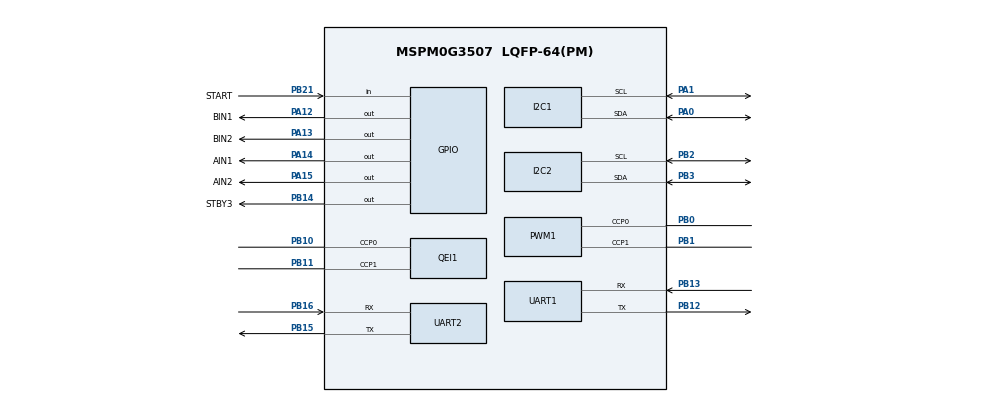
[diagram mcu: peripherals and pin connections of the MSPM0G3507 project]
/**
 * These arguments were used when this file was generated. They will be automatically applied on subsequent loads
 * via the GUI or CLI. Run CLI with '--help' for additional information on how to override these arguments.
 * @cliArgs --device "MSPM0G350X" --part "Default" --package "LQFP-64(PM)" --product "mspm0_sdk@2.02.00.05"
 * @v2CliArgs --device "MSPM0G3507" --package "LQFP-64(PM)" --product "mspm0_sdk@2.02.00.05"
 * @versions {"tool":"1.21.1+3772"}
 */

/**
 * Import the modules used in this configuration.
 */
const GPIO   = scripting.addModule("/ti/driverlib/GPIO", {}, false);
const GPIO1  = GPIO.addInstance();
const GPIO2  = GPIO.addInstance();
const GPIO3  = GPIO.addInstance();
const ADC12  = scripting.addModule("/ti/driverlib/ADC12", {}, false);
const ADC121 = ADC12.addInstance();
const I2C    = scripting.addModule("/ti/driverlib/I2C", {}, false);
const I2C1   = I2C.addInstance();
const I2C2   = I2C.addInstance();
const PWM    = scripting.addModule("/ti/driverlib/PWM", {}, false);
const PWM1   = PWM.addInstance();
const QEI    = scripting.addModule("/ti/driverlib/QEI", {}, false);
const QEI1   = QEI.addInstance();
const SYSCTL = scripting.addModule("/ti/driverlib/SYSCTL");
const UART   = scripting.addModule("/ti/driverlib/UART", {}, false);
const UART1  = UART.addInstance();
const UART2  = UART.addInstance();
const WWDT   = scripting.addModule("/ti/driverlib/WWDT", {}, false);
const WWDT1  = WWDT.addInstance();

/**
 * Write custom configuration values to the imported modules.
 */
GPIO1.$name                         = "STBY";
GPIO1.port                          = "PORTB";
GPIO1.associatedPins[0].$name       = "STBY3";
GPIO1.associatedPins[0].pin.$assign = "PB14";

const Board = scripting.addModule("/ti/driverlib/Board", {}, false);

GPIO2.$name                         = "MOTO";
GPIO2.port                          = "PORTA";
GPIO2.associatedPins.create(4);
GPIO2.associatedPins[0].$name       = "AIN1";
GPIO2.associatedPins[0].pin.$assign = "PA14";
GPIO2.associatedPins[1].$name       = "AIN2";
GPIO2.associatedPins[1].pin.$assign = "PA15";
GPIO2.associatedPins[2].$name       = "BIN1";
GPIO2.associatedPins[2].pin.$assign = "PA12";
GPIO2.associatedPins[3].$name       = "BIN2";
GPIO2.associatedPins[3].pin.$assign = "PA13";

GPIO3.$name                              = "KEY";
GPIO3.port                               = "PORTB";
GPIO3.associatedPins[0].$name            = "START";
GPIO3.associatedPins[0].direction        = "INPUT";
GPIO3.associatedPins[0].internalResistor = "PULL_UP";
GPIO3.associatedPins[0].pin.$assign      = "PB21";

ADC121.$name                      = "BAT_ADC";
ADC121.sampClkSrc                 = "DL_ADC12_CLOCK_ULPCLK";
ADC121.sampClkDiv                 = "DL_ADC12_CLOCK_DIVIDE_8";
ADC121.adcMem0chansel             = "DL_ADC12_INPUT_CHAN_0";
ADC121.sampleTime0                = "125 us";
ADC121.powerDownMode              = "DL_ADC12_POWER_DOWN_MODE_MANUAL";
ADC121.peripheral.$assign         = "ADC0";
ADC121.peripheral.adcPin0.$assign = "PA27";
ADC121.adcPin0Config.$name        = "ti_driverlib_gpio_GPIOPinGeneric12";

I2C1.$name                             = "OLED";
I2C1.basicEnableController             = true;
I2C1.basicControllerStandardBusSpeed   = "Standard";
I2C1.peripheral.$assign                = "I2C0";
I2C1.peripheral.sdaPin.$assign         = "PA0";
I2C1.peripheral.sclPin.$assign         = "PA1";
I2C1.sdaPinConfig.$name                = "ti_driverlib_gpio_GPIOPinGeneric0";
I2C1.sdaPinConfig.hideOutputInversion  = scripting.forceWrite(false);
I2C1.sdaPinConfig.onlyInternalResistor = scripting.forceWrite(false);
I2C1.sdaPinConfig.passedPeripheralType = scripting.forceWrite("Digital");
I2C1.sclPinConfig.$name                = "ti_driverlib_gpio_GPIOPinGeneric1";
I2C1.sclPinConfig.hideOutputInversion  = scripting.forceWrite(false);
I2C1.sclPinConfig.onlyInternalResistor = scripting.forceWrite(false);
I2C1.sclPinConfig.passedPeripheralType = scripting.forceWrite("Digital");

I2C2.$name                             = "IMU20948";
I2C2.basicEnableController             = true;
I2C2.basicControllerStandardBusSpeed   = "Standard";
I2C2.peripheral.$assign                = "I2C1";
I2C2.peripheral.sdaPin.$assign         = "PB3";
I2C2.peripheral.sclPin.$assign         = "PB2";
I2C2.sdaPinConfig.$name                = "ti_driverlib_gpio_GPIOPinGeneric2";
I2C2.sdaPinConfig.hideOutputInversion  = scripting.forceWrite(false);
I2C2.sdaPinConfig.onlyInternalResistor = scripting.forceWrite(false);
I2C2.sdaPinConfig.passedPeripheralType = scripting.forceWrite("Digital");
I2C2.sclPinConfig.$name                = "ti_driverlib_gpio_GPIOPinGeneric3";
I2C2.sclPinConfig.hideOutputInversion  = scripting.forceWrite(false);
I2C2.sclPinConfig.onlyInternalResistor = scripting.forceWrite(false);
I2C2.sclPinConfig.passedPeripheralType = scripting.forceWrite("Digital");

PWM1.$name                      = "PWM_0";
PWM1.clockDivider               = 8;
PWM1.timerCount                 = 200;
PWM1.timerStartTimer            = true;
PWM1.peripheral.$assign         = "TIMA1";
PWM1.peripheral.ccp0Pin.$assign = "PB0";
PWM1.peripheral.ccp1Pin.$assign = "PB1";
PWM1.PWM_CHANNEL_0.$name        = "ti_driverlib_pwm_PWMTimerCC0";
PWM1.PWM_CHANNEL_0.dutyCycle    = 0;
PWM1.PWM_CHANNEL_1.$name        = "ti_driverlib_pwm_PWMTimerCC1";
PWM1.PWM_CHANNEL_1.dutyCycle    = 0;
PWM1.ccp0PinConfig.$name        = "ti_driverlib_gpio_GPIOPinGeneric8";
PWM1.ccp1PinConfig.$name        = "ti_driverlib_gpio_GPIOPinGeneric9";

QEI1.$name                              = "QEI_R";
QEI1.clockDivider                       = 8;
QEI1.peripheral.$assign                 = "TIMG8";
QEI1.peripheral.ccp0Pin.$assign         = "PB10";
QEI1.peripheral.ccp1Pin.$assign         = "PB11";
QEI1.ccp0PinConfig.$name                = "ti_driverlib_gpio_GPIOPinGeneric10";
QEI1.ccp0PinConfig.hideOutputInversion  = scripting.forceWrite(false);
QEI1.ccp0PinConfig.onlyInternalResistor = scripting.forceWrite(false);
QEI1.ccp0PinConfig.passedPeripheralType = scripting.forceWrite("Digital");
QEI1.ccp1PinConfig.$name                = "ti_driverlib_gpio_GPIOPinGeneric11";
QEI1.ccp1PinConfig.hideOutputInversion  = scripting.forceWrite(false);
QEI1.ccp1PinConfig.onlyInternalResistor = scripting.forceWrite(false);
QEI1.ccp1PinConfig.passedPeripheralType = scripting.forceWrite("Digital");

SYSCTL.forceDefaultClkConfig = true;

UART1.$name                            = "IR8";
UART1.uartClkDiv                       = "8";
UART1.targetBaudRate                   = 115200;
UART1.enabledInterrupts                = ["RX"];
UART1.peripheral.$assign               = "UART3";
UART1.peripheral.rxPin.$assign         = "PB13";
UART1.peripheral.txPin.$assign         = "PB12";
UART1.txPinConfig.$name                = "ti_driverlib_gpio_GPIOPinGeneric4";
UART1.txPinConfig.direction            = scripting.forceWrite("OUTPUT");
UART1.txPinConfig.hideOutputInversion  = scripting.forceWrite(false);
UART1.txPinConfig.onlyInternalResistor = scripting.forceWrite(false);
UART1.txPinConfig.passedPeripheralType = scripting.forceWrite("Digital");
UART1.rxPinConfig.$name                = "ti_driverlib_gpio_GPIOPinGeneric5";
UART1.rxPinConfig.hideOutputInversion  = scripting.forceWrite(false);
UART1.rxPinConfig.onlyInternalResistor = scripting.forceWrite(false);
UART1.rxPinConfig.passedPeripheralType = scripting.forceWrite("Digital");

UART2.$name                            = "BT";
UART2.uartClkDiv                       = "8";
UART2.enabledInterrupts                = ["RX"];
UART2.peripheral.$assign               = "UART2";
UART2.peripheral.rxPin.$assign         = "PB16";
UART2.peripheral.txPin.$assign         = "PB15";
UART2.txPinConfig.$name                = "ti_driverlib_gpio_GPIOPinGeneric6";
UART2.txPinConfig.direction            = scripting.forceWrite("OUTPUT");
UART2.txPinConfig.hideOutputInversion  = scripting.forceWrite(false);
UART2.txPinConfig.onlyInternalResistor = scripting.forceWrite(false);
UART2.txPinConfig.passedPeripheralType = scripting.forceWrite("Digital");
UART2.rxPinConfig.$name                = "ti_driverlib_gpio_GPIOPinGeneric7";
UART2.rxPinConfig.hideOutputInversion  = scripting.forceWrite(false);
UART2.rxPinConfig.onlyInternalResistor = scripting.forceWrite(false);
UART2.rxPinConfig.passedPeripheralType = scripting.forceWrite("Digital");

WWDT1.$name               = "WWDT0";
WWDT1.sleepMode           = true;
WWDT1.window0ClosedPeriod = "0";
WWDT1.peripheral.$assign  = "WWDT0";

/**
 * Pinmux solution for unlocked pins/peripherals. This ensures that minor changes to the automatic solver in a future
 * version of the tool will not impact the pinmux you originally saw.  These lines can be completely deleted in order to
 * re-solve from scratch.
 */
Board.peripheral.$suggestSolution          = "DEBUGSS";
Board.peripheral.swclkPin.$suggestSolution = "PA20";
Board.peripheral.swdioPin.$suggestSolution = "PA19";
SYSCTL.peripheral.$suggestSolution         = "SYSCTL";
